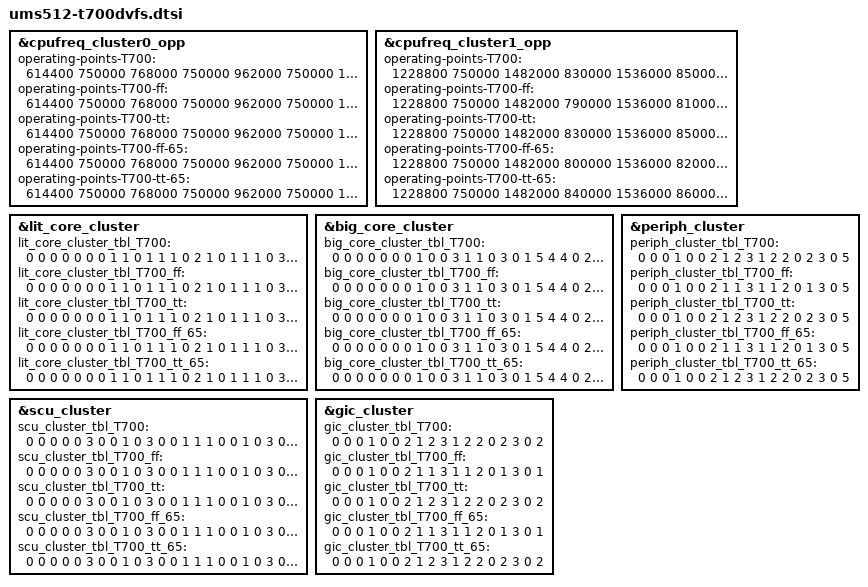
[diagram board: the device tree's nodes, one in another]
// SPDX-License-Identifier: (GPL-2.0+ OR MIT)
/*
 * Unisoc Sharkl5Pro platform T700 SOC DVFS DTS file
 *
 * Copyright (C) 2020, Unisoc Communications Inc.
 */

#include "sharkl5Pro.dtsi"
#include "ums512.dtsi"

&cpufreq_cluster0_opp {
	/* operating-points-T700-0-0
	 * T700-soc_ver 0-binning 0-temp
	 */
	operating-points-T700 = <
		/* kHZ   uV */
		614400  750000
		768000  750000
		962000  750000
		1144000 750000
		1228800 756250
		1482000 843750
		1536000 862500
		1716000 925000
		1820000 962500
	>;

	operating-points-T700-ff = <
		/* kHZ   uV */
		614400  750000
		768000  750000
		962000  750000
		1144000 750000
		1228800 750000
		1482000 803125
		1536000 821875
		1716000 884375
		1820000 921875
	>;

	operating-points-T700-tt = <
		/* kHZ   uV */
		614400  750000
		768000  750000
		962000  750000
		1144000 750000
		1228800 756250
		1482000 843750
		1536000 862500
		1716000 925000
		1820000 962500
	>;

	operating-points-T700-ff-65 = <
		/* kHZ   uV */
		614400  750000
		768000  750000
		962000  750000
		1144000 750000
		1228800 750000
		1482000 812500
		1536000 834375
		1716000 903125
		1820000 940625
	>;

	operating-points-T700-tt-65 = <
		/* kHZ   uV */
		614400  750000
		768000  750000
		962000  750000
		1144000 750000
		1228800 759375
		1482000 856250
		1536000 875000
		1716000 943750
		1820000 981250
	>;
};

&cpufreq_cluster1_opp {
	operating-points-T700 = <
		/* kHZ   uV */
		1228800	750000
		1482000	830000
		1536000	850000
		1742000 930000
		1820000 960000
	>;

	operating-points-T700-ff = <
		/* kHZ   uV */
		1228800	750000
		1482000	790000
		1536000	810000
		1742000 890000
		1820000 920000
	>;

	operating-points-T700-tt = <
		/* kHZ   uV */
		1228800	750000
		1482000	830000
		1536000	850000
		1742000 930000
		1820000 960000
	>;

	operating-points-T700-ff-65 = <
		/* kHZ   uV */
		1228800	750000
		1482000	800000
		1536000	820000
		1742000 910000
		1820000 940000
	>;

	operating-points-T700-tt-65 = <
		/* kHZ   uV */
		1228800	750000
		1482000	840000
		1536000	860000
		1742000 950000
		1820000 980000
	>;
};

&lit_core_cluster{
	/* lit_core_cluster_tbl_T700_0_0
	 * T700-soc_ver 0-binning 0-temp
	 * sel, div, vol, vote_scu, vote_peri, vote_gic, mpllx
	 */
	lit_core_cluster_tbl_T700 = <
		0 0 0 0 0 0 0
		1 1 0 1 1 1 0
		2 1 0 1 1 1 0
		3 0 0 2 1 1 0
		3 0 0 3 1 1 1
		1 0 1 4 1 1 0
		3 0 2 5 4 4 2
		2 0 3 6 4 4 0
		3 0 4 7 4 5 3
		3 0 5 8 4 5 4
		3 0 5 8 4 5 4
	>;

	lit_core_cluster_tbl_T700_ff = <
		0 0 0 0 0 0 0
		1 1 0 1 1 1 0
		2 1 0 1 1 1 0
		3 0 0 2 1 1 0
		3 0 0 3 1 1 1
		1 0 0 4 1 1 0
		3 0 1 5 4 4 2
		2 0 2 6 4 4 0
		3 0 3 7 4 5 3
		3 0 4 8 4 5 4
		3 0 4 8 4 5 4
	>;

	lit_core_cluster_tbl_T700_tt = <
		0 0 0 0 0 0 0
		1 1 0 1 1 1 0
		2 1 0 1 1 1 0
		3 0 0 2 1 1 0
		3 0 0 3 1 1 1
		1 0 1 4 1 1 0
		3 0 2 5 4 4 2
		2 0 3 6 4 4 0
		3 0 4 7 4 5 3
		3 0 5 8 4 5 4
		3 0 5 8 4 5 4
	>;

	lit_core_cluster_tbl_T700_ff_65 = <
		0 0 0 0 0 0 0
		1 1 0 1 1 1 0
		2 1 0 1 1 1 0
		3 0 0 2 1 1 0
		3 0 0 3 1 1 1
		1 0 0 4 1 1 0
		3 0 1 5 4 4 2
		2 0 2 6 4 4 0
		3 0 3 7 4 5 3
		3 0 4 8 4 5 4
		3 0 4 8 4 5 4
	>;

	lit_core_cluster_tbl_T700_tt_65 = <
		0 0 0 0 0 0 0
		1 1 0 1 1 1 0
		2 1 0 1 1 1 0
		3 0 0 2 1 1 0
		3 0 0 3 1 1 1
		1 0 1 4 1 1 0
		3 0 2 5 4 4 2
		2 0 3 6 4 4 0
		3 0 4 7 4 5 3
		3 0 5 8 4 5 4
		3 0 5 8 4 5 4
	>;
};

&big_core_cluster {
	/* sel, div, vol, vote_scu, vote_peri, vote_gic, mpllx */
	big_core_cluster_tbl_T700 = <
		0 0 0 0 0 0 0
		1 0 0 3 1 1 0
		3 0 1 5 4 4 0
		2 0 2 6 4 4 0
		3 0 3 7 4 5 1
		3 0 4 8 4 5 2
		3 0 4 8 4 5 2
	>;

	big_core_cluster_tbl_T700_ff = <
		0 0 0 0 0 0 0
		1 0 0 3 1 1 0
		3 0 1 5 4 4 0
		2 0 2 6 4 4 0
		3 0 3 7 4 5 1
		3 0 4 8 4 5 2
		3 0 4 8 4 5 2
	>;

	big_core_cluster_tbl_T700_tt = <
		0 0 0 0 0 0 0
		1 0 0 3 1 1 0
		3 0 1 5 4 4 0
		2 0 2 6 4 4 0
		3 0 3 7 4 5 1
		3 0 4 8 4 5 2
		3 0 4 8 4 5 2
	>;

	big_core_cluster_tbl_T700_ff_65 = <
		0 0 0 0 0 0 0
		1 0 0 3 1 1 0
		3 0 1 5 4 4 0
		2 0 2 6 4 4 0
		3 0 3 7 4 5 1
		3 0 4 8 4 5 2
		3 0 4 8 4 5 2
	>;

	big_core_cluster_tbl_T700_tt_65 = <
		0 0 0 0 0 0 0
		1 0 0 3 1 1 0
		3 0 1 5 4 4 0
		2 0 2 6 4 4 0
		3 0 3 7 4 5 1
		3 0 4 8 4 5 2
		3 0 4 8 4 5 2
	>;
};

&scu_cluster {
	/* sel div vol ace_div mpllx */
	scu_cluster_tbl_T700 = <
		0 0 0 0 0
		3 0 0 1 0
		3 0 0 1 1
		1 0 0 1 0
		3 0 1 1 2
		3 0 2 1 3
		3 0 3 1 4
		3 0 4 1 5
		3 0 5 1 6
		3 0 5 1 6
	>;

	scu_cluster_tbl_T700_ff = <
		0 0 0 0 0
		3 0 0 1 0
		3 0 0 1 1
		1 0 0 1 0
		3 0 0 1 2
		3 0 0 1 3
		3 0 1 1 4
		3 0 2 1 5
		3 0 3 1 6
		3 0 4 1 6
	>;

	scu_cluster_tbl_T700_tt = <
		0 0 0 0 0
		3 0 0 1 0
		3 0 0 1 1
		1 0 0 1 0
		3 0 0 1 2
		3 0 1 1 3
		3 0 2 1 4
		3 0 3 1 5
		3 0 4 1 6
		3 0 5 1 6
	>;

	scu_cluster_tbl_T700_ff_65 = <
		0 0 0 0 0
		3 0 0 1 0
		3 0 0 1 1
		1 0 0 1 0
		3 0 0 1 2
		3 0 0 1 3
		3 0 1 1 4
		3 0 2 1 5
		3 0 3 1 6
		3 0 4 1 6
	>;

	scu_cluster_tbl_T700_tt_65 = <
		0 0 0 0 0
		3 0 0 1 0
		3 0 0 1 1
		1 0 0 1 0
		3 0 0 1 2
		3 0 1 1 3
		3 0 2 1 4
		3 0 3 1 5
		3 0 4 1 6
		3 0 5 1 6
	>;
};

&periph_cluster{
	/* sel div vol */
	periph_cluster_tbl_T700 = <
		0 0 0
		1 0 0
		2 1 2
		3 1 2
		2 0 2
		3 0 5
	>;

	periph_cluster_tbl_T700_ff = <
		0 0 0
		1 0 0
		2 1 1
		3 1 1
		2 0 1
		3 0 5
	>;

	periph_cluster_tbl_T700_tt = <
		0 0 0
		1 0 0
		2 1 2
		3 1 2
		2 0 2
		3 0 5
	>;

	periph_cluster_tbl_T700_ff_65 = <
		0 0 0
		1 0 0
		2 1 1
		3 1 1
		2 0 1
		3 0 5
	>;

	periph_cluster_tbl_T700_tt_65 = <
		0 0 0
		1 0 0
		2 1 2
		3 1 2
		2 0 2
		3 0 5
	>;
};

&gic_cluster {
	/*sel div vol*/
	gic_cluster_tbl_T700 = <
		0 0 0
		1 0 0
		2 1 2
		3 1 2
		2 0 2
		3 0 2
	>;

	gic_cluster_tbl_T700_ff = <
		0 0 0
		1 0 0
		2 1 1
		3 1 1
		2 0 1
		3 0 1
	>;

	gic_cluster_tbl_T700_tt = <
		0 0 0
		1 0 0
		2 1 2
		3 1 2
		2 0 2
		3 0 2
	>;

	gic_cluster_tbl_T700_ff_65 = <
		0 0 0
		1 0 0
		2 1 1
		3 1 1
		2 0 1
		3 0 1
	>;

	gic_cluster_tbl_T700_tt_65 = <
		0 0 0
		1 0 0
		2 1 2
		3 1 2
		2 0 2
		3 0 2
	>;
};
